CM_ "AUTOGENERATED FILE, DO NOT EDIT";

CM_ "Imported file _community.dbc starts here";
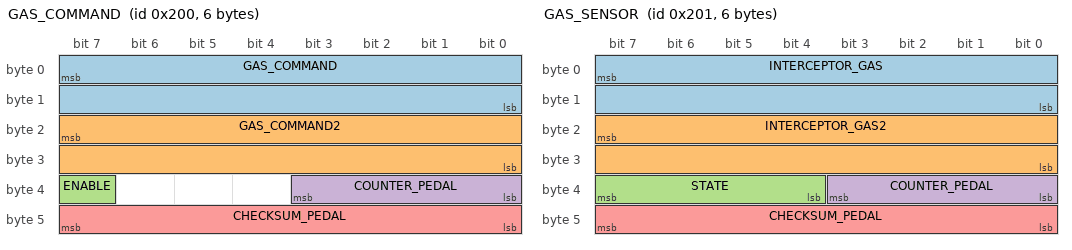
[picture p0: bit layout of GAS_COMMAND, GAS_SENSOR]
BO_ 512 GAS_COMMAND: 6 EON
 SG_ GAS_COMMAND : 7|16@0+ (0.253984064,-83.3) [0|1] "" INTERCEPTOR
 SG_ GAS_COMMAND2 : 23|16@0+ (0.126992032,-83.3) [0|1] "" INTERCEPTOR
 SG_ ENABLE : 39|1@0+ (1,0) [0|1] "" INTERCEPTOR
 SG_ COUNTER_PEDAL : 35|4@0+ (1,0) [0|15] "" INTERCEPTOR
 SG_ CHECKSUM_PEDAL : 47|8@0+ (1,0) [0|255] "" INTERCEPTOR

BO_ 513 GAS_SENSOR: 6 INTERCEPTOR
 SG_ INTERCEPTOR_GAS : 7|16@0+ (1,0) [0|1] "" EON
 SG_ INTERCEPTOR_GAS2 : 23|16@0+ (1,0) [0|1] "" EON
 SG_ STATE : 39|4@0+ (1,0) [0|15] "" EON
 SG_ COUNTER_PEDAL : 35|4@0+ (1,0) [0|15] "" EON
 SG_ CHECKSUM_PEDAL : 47|8@0+ (1,0) [0|255] "" EON

VAL_ 513 STATE 5 "FAULT_TIMEOUT" 4 "FAULT_STARTUP" 3 "FAULT_SCE" 2 "FAULT_SEND" 1 "FAULT_BAD_CHECKSUM" 0 "NO_FAULT" ;

CM_ "Imported file _honda_common.dbc starts here";
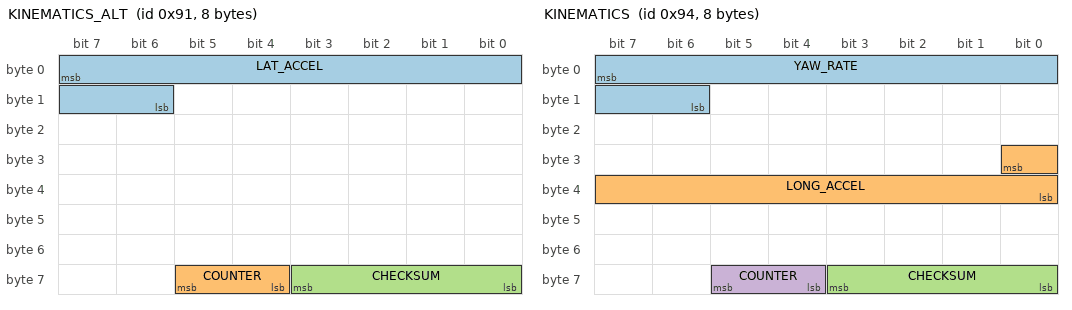
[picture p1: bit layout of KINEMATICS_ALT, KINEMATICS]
BO_ 145 KINEMATICS_ALT: 8 XXX
 SG_ LAT_ACCEL : 7|10@0+ (0.02,-512) [-20|20] "m/s2" EON
 SG_ COUNTER : 61|2@0+ (1,0) [0|3] "" EON
 SG_ CHECKSUM : 59|4@0+ (1,0) [0|3] "" EON

BO_ 148 KINEMATICS: 8 XXX
 SG_ YAW_RATE : 7|10@0+ (0.25,-128) [-128|127.75] "deg/s" EON
 SG_ LONG_ACCEL : 24|9@0- (-0.049,0) [-12.544|12.544] "m/s2" EON
 SG_ CHECKSUM : 59|4@0+ (1,0) [0|3] "" EON
 SG_ COUNTER : 61|2@0+ (1,0) [0|3] "" EON

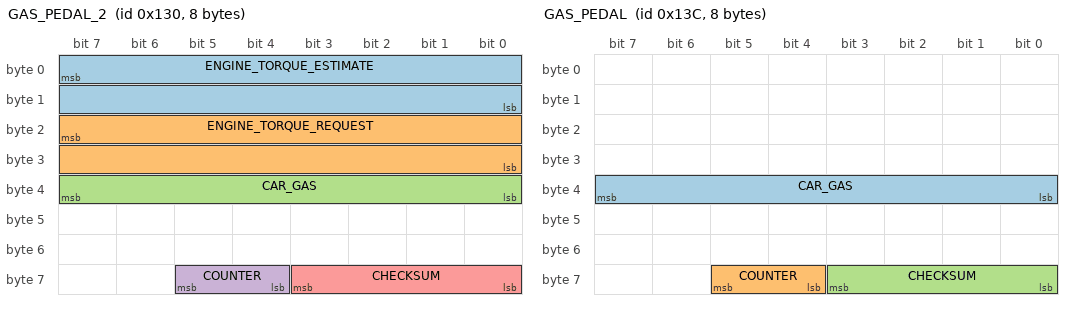
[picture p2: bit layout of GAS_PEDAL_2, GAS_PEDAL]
BO_ 304 GAS_PEDAL_2: 8 PCM
 SG_ ENGINE_TORQUE_ESTIMATE : 7|16@0- (1,0) [-1000|1000] "Nm" EON
 SG_ ENGINE_TORQUE_REQUEST : 23|16@0- (1,0) [-1000|1000] "Nm" EON
 SG_ CAR_GAS : 39|8@0+ (1,0) [0|255] "" EON
 SG_ COUNTER : 61|2@0+ (1,0) [0|3] "" EON
 SG_ CHECKSUM : 59|4@0+ (1,0) [0|15] "" EON

BO_ 316 GAS_PEDAL: 8 PCM
 SG_ CAR_GAS : 39|8@0+ (1,0) [0|255] "" EON
 SG_ COUNTER : 61|2@0+ (1,0) [0|3] "" EON
 SG_ CHECKSUM : 59|4@0+ (1,0) [0|15] "" EON

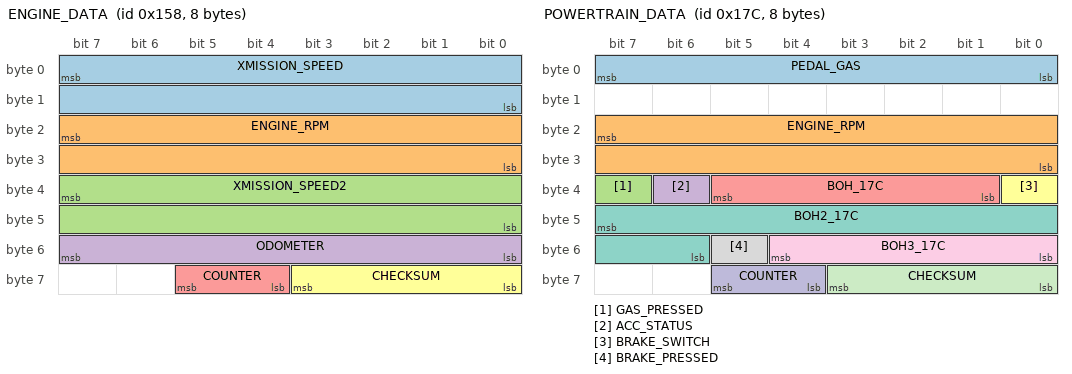
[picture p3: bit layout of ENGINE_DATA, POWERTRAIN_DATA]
BO_ 344 ENGINE_DATA: 8 PCM
 SG_ XMISSION_SPEED : 7|16@0+ (0.01,0) [0|250] "kph" EON
 SG_ ENGINE_RPM : 23|16@0+ (1,0) [0|15000] "rpm" EON
 SG_ XMISSION_SPEED2 : 39|16@0+ (0.01,0) [0|250] "kph" EON
 SG_ ODOMETER : 55|8@0+ (10,0) [0|2550] "m" XXX
 SG_ COUNTER : 61|2@0+ (1,0) [0|3] "" EON
 SG_ CHECKSUM : 59|4@0+ (1,0) [0|15] "" EON

BO_ 380 POWERTRAIN_DATA: 8 PCM
 SG_ PEDAL_GAS : 7|8@0+ (1,0) [0|255] "" EON
 SG_ ENGINE_RPM : 23|16@0+ (1,0) [0|15000] "rpm" EON
 SG_ GAS_PRESSED : 39|1@0+ (1,0) [0|1] "" EON
 SG_ ACC_STATUS : 38|1@0+ (1,0) [0|1] "" EON
 SG_ BOH_17C : 37|5@0+ (1,0) [0|1] "" EON
 SG_ BRAKE_SWITCH : 32|1@0+ (1,0) [0|1] "" EON
 SG_ BOH2_17C : 47|10@0+ (1,0) [0|1] "" EON
 SG_ BRAKE_PRESSED : 53|1@0+ (1,0) [0|1] "" EON
 SG_ BOH3_17C : 52|5@0+ (1,0) [0|1] "" EON
 SG_ COUNTER : 61|2@0+ (1,0) [0|3] "" EON
 SG_ CHECKSUM : 59|4@0+ (1,0) [0|15] "" EON

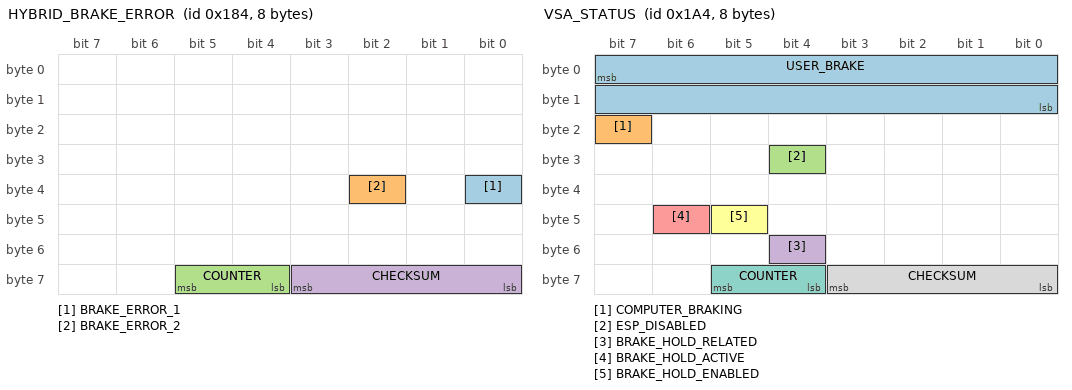
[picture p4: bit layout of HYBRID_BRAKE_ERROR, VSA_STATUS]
BO_ 388 HYBRID_BRAKE_ERROR: 8 XXX
 SG_ BRAKE_ERROR_1 : 32|1@0+ (1,0) [0|1] "" EON
 SG_ BRAKE_ERROR_2 : 34|1@0+ (1,0) [0|1] "" EON
 SG_ COUNTER : 61|2@0+ (1,0) [0|3] "" EON
 SG_ CHECKSUM : 59|4@0+ (1,0) [0|3] "" EON

BO_ 420 VSA_STATUS: 8 VSA
 SG_ USER_BRAKE : 7|16@0+ (0.015625,-1.609375) [0|1000] "" EON
 SG_ COMPUTER_BRAKING : 23|1@0+ (1,0) [0|1] "" EON
 SG_ ESP_DISABLED : 28|1@0+ (1,0) [0|1] "" EON
 SG_ BRAKE_HOLD_RELATED : 52|1@0+ (1,0) [0|1] "" XXX
 SG_ BRAKE_HOLD_ACTIVE : 46|1@0+ (1,0) [0|1] "" EON
 SG_ BRAKE_HOLD_ENABLED : 45|1@0+ (1,0) [0|1] "" EON
 SG_ COUNTER : 61|2@0+ (1,0) [0|3] "" EON
 SG_ CHECKSUM : 59|4@0+ (1,0) [0|15] "" EON

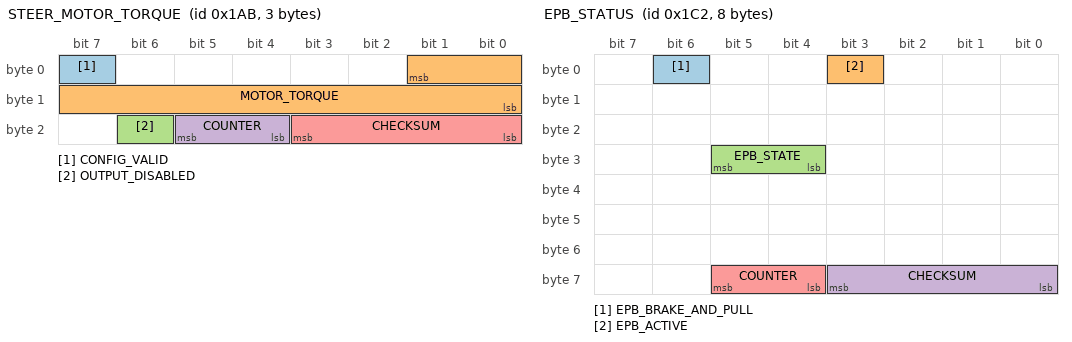
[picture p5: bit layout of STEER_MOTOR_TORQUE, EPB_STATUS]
BO_ 427 STEER_MOTOR_TORQUE: 3 EPS
 SG_ CONFIG_VALID : 7|1@0+ (1,0) [0|1] "" EON
 SG_ MOTOR_TORQUE : 1|10@0+ (1,0) [0|256] "" EON
 SG_ OUTPUT_DISABLED : 22|1@0+ (1,0) [0|1] "" EON
 SG_ COUNTER : 21|2@0+ (1,0) [0|3] "" EON
 SG_ CHECKSUM : 19|4@0+ (1,0) [0|15] "" EON

BO_ 450 EPB_STATUS: 8 XXX
 SG_ EPB_BRAKE_AND_PULL : 6|1@0+ (1,0) [0|1] "" XXX
 SG_ EPB_ACTIVE : 3|1@0+ (1,0) [0|1] "" XXX
 SG_ EPB_STATE : 29|2@0+ (1,0) [0|1] "" XXX
 SG_ CHECKSUM : 59|4@0+ (1,0) [0|15] "" XXX
 SG_ COUNTER : 61|2@0+ (1,0) [0|3] "" XXX

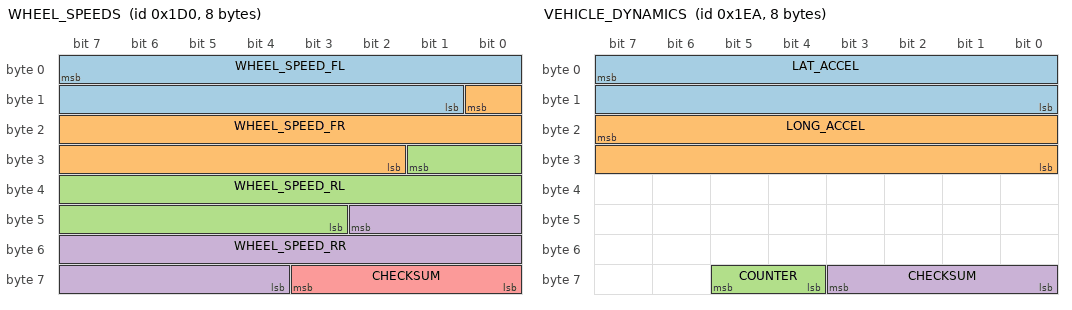
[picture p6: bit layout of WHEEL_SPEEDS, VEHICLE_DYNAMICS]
BO_ 464 WHEEL_SPEEDS: 8 VSA
 SG_ WHEEL_SPEED_FL : 7|15@0+ (0.01,0) [0|250] "kph" EON
 SG_ WHEEL_SPEED_FR : 8|15@0+ (0.01,0) [0|250] "kph" EON
 SG_ WHEEL_SPEED_RL : 25|15@0+ (0.01,0) [0|250] "kph" EON
 SG_ WHEEL_SPEED_RR : 42|15@0+ (0.01,0) [0|250] "kph" EON
 SG_ CHECKSUM : 59|4@0+ (1,0) [0|3] "" EON

BO_ 490 VEHICLE_DYNAMICS: 8 VSA
 SG_ LAT_ACCEL : 7|16@0- (0.0015,0) [-20|20] "m/s2" EON
 SG_ LONG_ACCEL : 23|16@0- (0.0015,0) [-20|20] "m/s2" EON
 SG_ COUNTER : 61|2@0+ (1,0) [0|3] "" EON
 SG_ CHECKSUM : 59|4@0+ (1,0) [0|3] "" EON

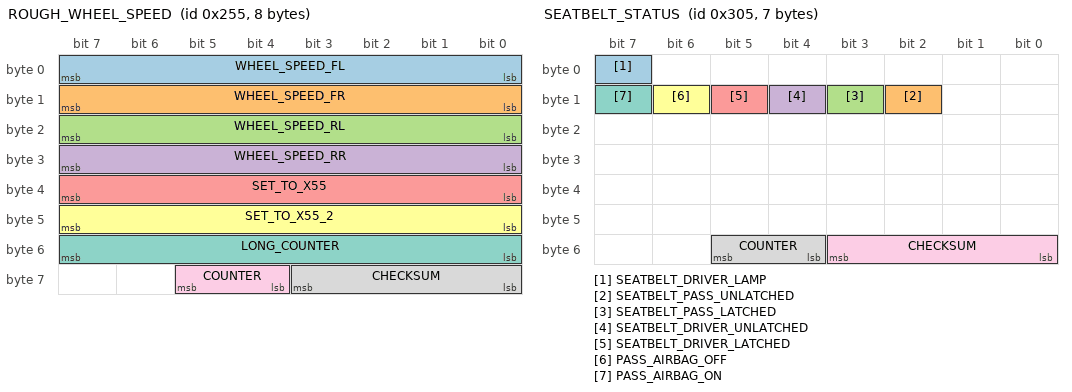
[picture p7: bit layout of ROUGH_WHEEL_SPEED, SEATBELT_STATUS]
BO_ 597 ROUGH_WHEEL_SPEED: 8 VSA
 SG_ WHEEL_SPEED_FL : 7|8@0+ (1,0) [0|255] "kph" EON
 SG_ WHEEL_SPEED_FR : 15|8@0+ (1,0) [0|255] "kph" EON
 SG_ WHEEL_SPEED_RL : 23|8@0+ (1,0) [0|255] "kph" EON
 SG_ WHEEL_SPEED_RR : 31|8@0+ (1,0) [0|255] "kph" EON
 SG_ SET_TO_X55 : 39|8@0+ (1,0) [0|255] "" EON
 SG_ SET_TO_X55_2 : 47|8@0+ (1,0) [0|255] "" EON
 SG_ LONG_COUNTER : 55|8@0+ (1,0) [0|255] "" EON
 SG_ CHECKSUM : 59|4@0+ (1,0) [0|15] "" EON
 SG_ COUNTER : 61|2@0+ (1,0) [0|3] "" EON

BO_ 773 SEATBELT_STATUS: 7 BDY
 SG_ SEATBELT_DRIVER_LAMP : 7|1@0+ (1,0) [0|1] "" EON
 SG_ SEATBELT_PASS_UNLATCHED : 10|1@0+ (1,0) [0|1] "" EON
 SG_ SEATBELT_PASS_LATCHED : 11|1@0+ (1,0) [0|1] "" EON
 SG_ SEATBELT_DRIVER_UNLATCHED : 12|1@0+ (1,0) [0|1] "" EON
 SG_ SEATBELT_DRIVER_LATCHED : 13|1@0+ (1,0) [0|1] "" EON
 SG_ PASS_AIRBAG_OFF : 14|1@0+ (1,0) [0|1] "" EON
 SG_ PASS_AIRBAG_ON : 15|1@0+ (1,0) [0|1] "" EON
 SG_ COUNTER : 53|2@0+ (1,0) [0|3] "" EON
 SG_ CHECKSUM : 51|4@0+ (1,0) [0|3] "" EON

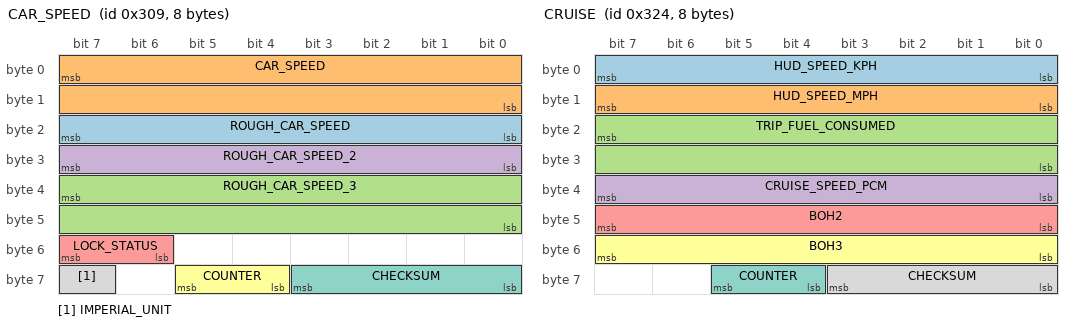
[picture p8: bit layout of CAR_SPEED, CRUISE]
BO_ 777 CAR_SPEED: 8 PCM
 SG_ ROUGH_CAR_SPEED : 23|8@0+ (1,0) [0|255] "mph" XXX
 SG_ CAR_SPEED : 7|16@0+ (0.01,0) [0|65535] "kph" XXX
 SG_ ROUGH_CAR_SPEED_3 : 39|16@0+ (0.01,0) [0|65535] "kph" XXX
 SG_ ROUGH_CAR_SPEED_2 : 31|8@0+ (1,0) [0|255] "mph" XXX
 SG_ LOCK_STATUS : 55|2@0+ (1,0) [0|255] "" XXX
 SG_ COUNTER : 61|2@0+ (1,0) [0|3] "" XXX
 SG_ CHECKSUM : 59|4@0+ (1,0) [0|15] "" XXX
 SG_ IMPERIAL_UNIT : 63|1@0+ (1,0) [0|1] "" XXX

BO_ 780 ACC_HUD: 8 ADAS
 SG_ PCM_SPEED : 7|16@0+ (0.01,0) [0|250] "kph" BDY
 SG_ PCM_GAS : 23|8@0+ (1,0) [0|127] "" BDY
 SG_ CRUISE_SPEED : 31|8@0+ (1,0) [0|255] "kph" BDY
 SG_ DTC_MODE : 39|1@0+ (1,0) [0|1] "" BDY
 SG_ BRAKE_SYSTEM_ICON : 38|1@0+ (1,0) [0|1] "" BDY
 SG_ ACC_PROBLEM : 37|1@0+ (1,0) [0|1] "" BDY
 SG_ FCM_OFF : 35|1@0+ (1,0) [0|1] "" BDY
 SG_ FCM_OFF_2 : 36|1@0+ (1,0) [0|1] "" BDY
 SG_ FCM_PROBLEM : 34|1@0+ (1,0) [0|1] "" BDY
 SG_ RADAR_OBSTRUCTED : 33|1@0+ (1,0) [0|1] "" BDY
 SG_ ENABLE_MINI_CAR : 32|1@0+ (1,0) [0|1] "" BDY
 SG_ HUD_DISTANCE : 47|2@0+ (1,0) [0|3] "" BDY
 SG_ HUD_LEAD : 45|2@0+ (1,0) [0|3] "" BDY
 SG_ BOH_3 : 43|1@0+ (1,0) [0|3] "" BDY
 SG_ BOH_4 : 42|1@0+ (1,0) [0|3] "" BDY
 SG_ BOH_5 : 41|1@0+ (1,0) [0|3] "" BDY
 SG_ CRUISE_CONTROL_LABEL : 40|1@0+ (1,0) [0|3] "" BDY
 SG_ SET_ME_X01_2 : 55|1@0+ (1,0) [0|1] "" BDY
 SG_ IMPERIAL_UNIT : 54|1@0+ (1,0) [0|1] "" BDY
 SG_ ACC_ON : 52|1@0+ (1,0) [0|1] "" BDY
 SG_ CHIME : 51|3@0+ (1,0) [0|1] "" BDY
 SG_ SET_ME_X01 : 48|1@0+ (1,0) [0|1] "" BDY
 SG_ ICONS : 63|2@0+ (1,0) [0|1] "" BDY
 SG_ COUNTER : 61|2@0+ (1,0) [0|3] "" BDY
 SG_ CHECKSUM : 59|4@0+ (1,0) [0|3] "" BDY

BO_ 804 CRUISE: 8 PCM
 SG_ HUD_SPEED_KPH : 7|8@0+ (1,0) [0|255] "kph" EON
 SG_ HUD_SPEED_MPH : 15|8@0+ (1,0) [0|255] "mph" EON
 SG_ TRIP_FUEL_CONSUMED : 23|16@0+ (1,0) [0|255] "" EON
 SG_ CRUISE_SPEED_PCM : 39|8@0+ (1,0) [0|255] "" EON
 SG_ BOH2 : 47|8@0- (1,0) [0|255] "" EON
 SG_ BOH3 : 55|8@0+ (1,0) [0|255] "" EON
 SG_ COUNTER : 61|2@0+ (1,0) [0|3] "" EON
 SG_ CHECKSUM : 59|4@0+ (1,0) [0|15] "" EON

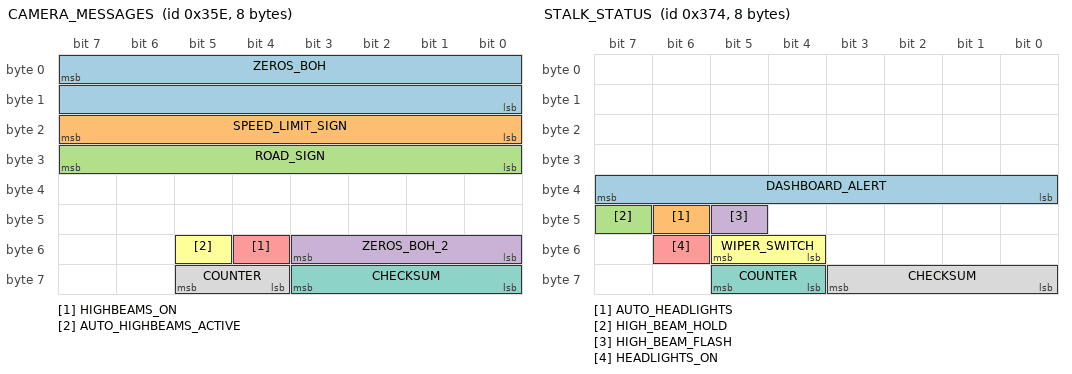
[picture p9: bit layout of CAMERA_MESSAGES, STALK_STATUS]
BO_ 862 CAMERA_MESSAGES: 8 CAM
 SG_ ZEROS_BOH : 7|16@0+ (1,0) [0|127] "" BDY
 SG_ SPEED_LIMIT_SIGN : 23|8@0+ (1,0) [0|255] "" XXX
 SG_ ROAD_SIGN : 31|8@0+ (1,0) [0|255] "" XXX
 SG_ ZEROS_BOH_2 : 51|4@0+ (1,0) [0|15] "" XXX
 SG_ HIGHBEAMS_ON : 52|1@0+ (1,0) [0|1] "" XXX
 SG_ AUTO_HIGHBEAMS_ACTIVE : 53|1@0+ (1,0) [0|1] "" XXX
 SG_ CHECKSUM : 59|4@0+ (1,0) [0|15] "" XXX
 SG_ COUNTER : 61|2@0+ (1,0) [0|3] "" XXX

BO_ 884 STALK_STATUS: 8 XXX
 SG_ DASHBOARD_ALERT : 39|8@0+ (1,0) [0|255] "" EON
 SG_ AUTO_HEADLIGHTS : 46|1@0+ (1,0) [0|1] "" EON
 SG_ HIGH_BEAM_HOLD : 47|1@0+ (1,0) [0|1] "" EON
 SG_ HIGH_BEAM_FLASH : 45|1@0+ (1,0) [0|1] "" EON
 SG_ HEADLIGHTS_ON : 54|1@0+ (1,0) [0|1] "" EON
 SG_ WIPER_SWITCH : 53|2@0+ (1,0) [0|3] "" XXX
 SG_ COUNTER : 61|2@0+ (1,0) [0|3] "" EON
 SG_ CHECKSUM : 59|4@0+ (1,0) [0|15] "" EON

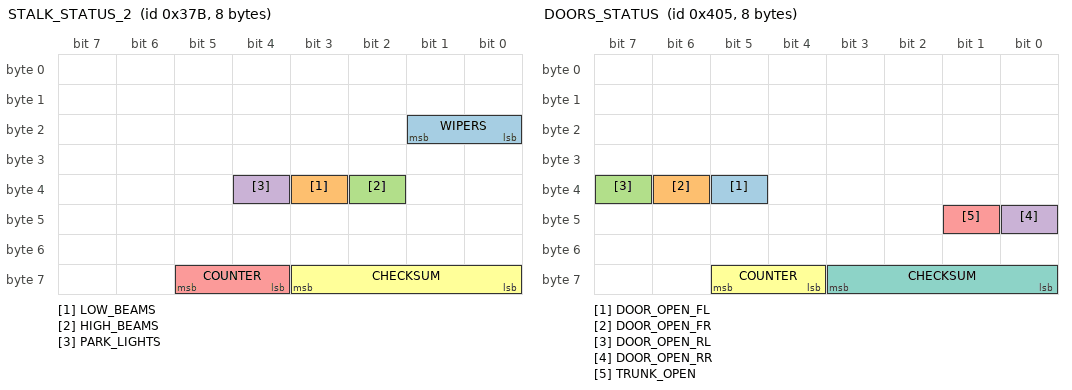
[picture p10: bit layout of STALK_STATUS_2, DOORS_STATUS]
BO_ 891 STALK_STATUS_2: 8 XXX
 SG_ WIPERS : 17|2@0+ (1,0) [0|3] "" EON
 SG_ LOW_BEAMS : 35|1@0+ (1,0) [0|1] "" XXX
 SG_ HIGH_BEAMS : 34|1@0+ (1,0) [0|1] "" XXX
 SG_ PARK_LIGHTS : 36|1@0+ (1,0) [0|1] "" XXX
 SG_ COUNTER : 61|2@0+ (1,0) [0|3] "" EON
 SG_ CHECKSUM : 59|4@0+ (1,0) [0|15] "" EON

BO_ 1029 DOORS_STATUS: 8 BDY
 SG_ DOOR_OPEN_FL : 37|1@0+ (1,0) [0|1] "" EON
 SG_ DOOR_OPEN_FR : 38|1@0+ (1,0) [0|1] "" EON
 SG_ DOOR_OPEN_RL : 39|1@0+ (1,0) [0|1] "" EON
 SG_ DOOR_OPEN_RR : 40|1@0+ (1,0) [0|1] "" EON
 SG_ TRUNK_OPEN : 41|1@0+ (1,0) [0|1] "" EON
 SG_ COUNTER : 61|2@0+ (1,0) [0|3] "" EON
 SG_ CHECKSUM : 59|4@0+ (1,0) [0|15] "" EON

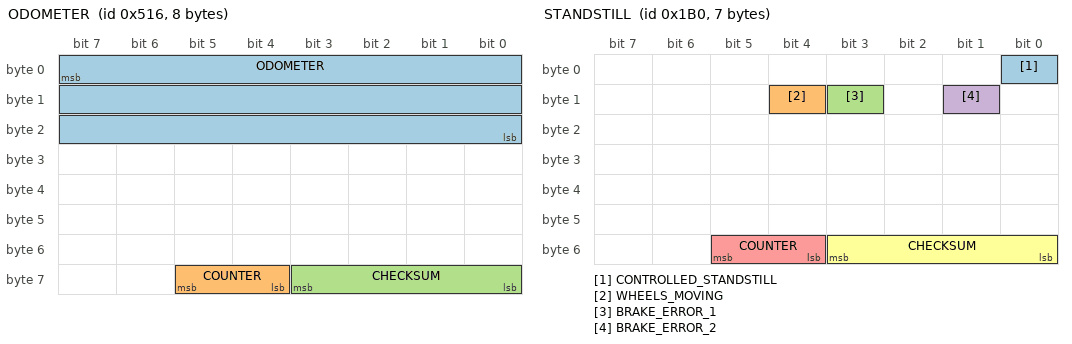
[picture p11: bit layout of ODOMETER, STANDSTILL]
BO_ 1302 ODOMETER: 8 XXX
 SG_ ODOMETER : 7|24@0+ (1,0) [0|16777215] "km" EON
 SG_ COUNTER : 61|2@0+ (1,0) [0|3] "" EON
 SG_ CHECKSUM : 59|4@0+ (1,0) [0|3] "" EON

CM_ SG_ 304 "Seems to be platform-agnostic";
CM_ SG_ 316 "Should exist on Nidec";
CM_ SG_ 420 BRAKE_HOLD_RELATED "On when Brake Hold engaged";
CM_ SG_ 490 LONG_ACCEL "wheel speed derivative, noisy and zero snapping";
CM_ SG_ 773 PASS_AIRBAG_ON "Might just be indicator light";
CM_ SG_ 773 PASS_AIRBAG_OFF "Might just be indicator light";
CM_ SG_ 780 CRUISE_SPEED "255 = no speed";
CM_ SG_ 780 PCM_SPEED "Used by Nidec";
CM_ SG_ 780 PCM_GAS "Used by Nidec";
CM_ SG_ 804 CRUISE_SPEED_PCM "255 = no speed";
CM_ SG_ 148 YAW_RATE "Vehicle yaw rate from the chassis yaw sensor, positive = clockwise (right turn), nominal zero 512 counts. Each car sits a few counts off that zero (2018 Clarity 508, 2019 Civic Bosch 513, both constant at every standstill), so learn it at standstill. Scale checked against GPS heading: Clarity 0.2494-0.2522, Civic Bosch 0.241-0.245 deg/s per count. Replaces an unused LAT_ACCEL definition (0.02, -512) that was not lateral acceleration.";
CM_ SG_ 148 LONG_ACCEL "Longitudinal accelerometer, gravity included (reads road grade at standstill), positive = accelerating. -0.049 m/s2 per count (about 0.005 g) against the comma IMU on 17 Clarity and 2 Civic Bosch routes, correlation 0.98-0.998; the former -0.02 read 2.4x low.";

CM_ SG_ 148 YAW_RATE "Vehicle yaw rate from the chassis yaw sensor, positive = clockwise (right turn), nominal zero 512 counts. Each car sits a few counts off that zero (2018 Clarity 508, 2019 Civic Bosch 513, both constant at every standstill), so learn it at standstill. Scale checked against GPS heading: Clarity 0.2494-0.2522, Civic Bosch 0.241-0.245 deg/s per count. Replaces an unused LAT_ACCEL definition (0.02, -512) that was not lateral acceleration.";
CM_ SG_ 148 LONG_ACCEL "Longitudinal accelerometer, gravity included (reads road grade at standstill), positive = accelerating. -0.049 m/s2 per count (about 0.005 g) against the comma IMU on 17 Clarity and 2 Civic Bosch routes, correlation 0.98-0.998; the former -0.02 read 2.4x low.";

VAL_ 450 EPB_STATE 3 "engaged" 2 "disengaging" 1 "engaging" 0 "disengaged" ;
VAL_ 780 CRUISE_SPEED 255 "no_speed" 252 "stopped";
VAL_ 780 HUD_LEAD 3 "acc_off" 2 "solid_car" 1 "dashed_car" 0 "no_car";
VAL_ 884 DASHBOARD_ALERT 0 "none" 51 "acc_problem" 55 "cmbs_problem" 75 "key_not_detected" 79 "fasten_seatbelt" 111 "lkas_problem" 131 "brake_system_problem" 132 "brake_hold_problem" 139 "tbd" 161 "door_open";
VAL_ 891 WIPERS 4 "High" 2 "Low" 0 "Off";

CM_ "Imported file _nidec_common.dbc starts here";
BO_ 432 STANDSTILL: 7 VSA
 SG_ CONTROLLED_STANDSTILL : 0|1@0+ (1,0) [0|1] "" EON
 SG_ WHEELS_MOVING : 12|1@0+ (1,0) [0|1] "" EON
 SG_ BRAKE_ERROR_1 : 11|1@0+ (1,0) [0|1] "" EON
 SG_ BRAKE_ERROR_2 : 9|1@0+ (1,0) [0|1] "" EON
 SG_ COUNTER : 53|2@0+ (1,0) [0|3] "" EON
 SG_ CHECKSUM : 51|4@0+ (1,0) [0|3] "" EON

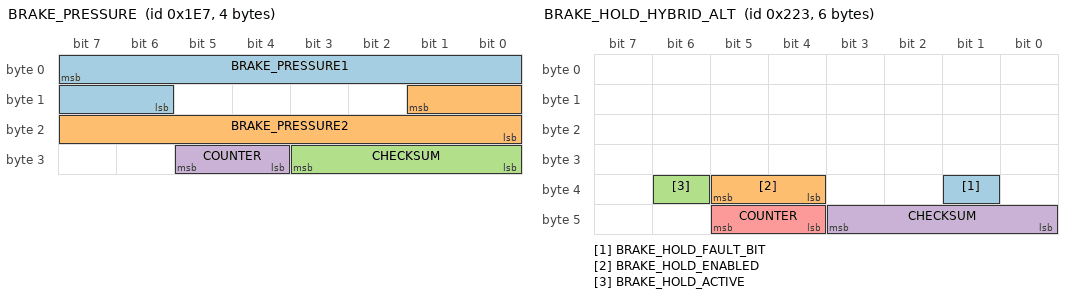
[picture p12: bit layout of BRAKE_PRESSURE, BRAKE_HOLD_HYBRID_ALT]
BO_ 487 BRAKE_PRESSURE: 4 VSA
 SG_ BRAKE_PRESSURE1 : 7|10@0+ (0.015625,-103) [0|1000] "" EON
 SG_ BRAKE_PRESSURE2 : 9|10@0+ (0.015625,-103) [0|1000] "" EON
 SG_ CHECKSUM : 27|4@0+ (1,0) [0|15] "" EON
 SG_ COUNTER : 29|2@0+ (1,0) [0|3] "" EON

BO_ 506 BRAKE_COMMAND: 8 ADAS
 SG_ COMPUTER_BRAKE : 7|10@0+ (1,0) [0|1] "" EBCM
 SG_ BRAKE_PUMP_REQUEST : 8|1@0+ (1,0) [0|1] "" EBCM
 SG_ BRAKE_PUMP_REQUEST_HYBRID : 11|1@0+ (1,0) [0|1] "" EBCM
 SG_ SET_ME_X00 : 23|3@0+ (1,0) [0|1] "" EBCM
 SG_ CRUISE_OVERRIDE : 20|1@0+ (1,0) [0|1] "" EBCM
 SG_ SET_ME_X00_2 : 19|1@0+ (1,0) [0|1] "" EBCM
 SG_ CRUISE_FAULT_CMD : 18|1@0+ (1,0) [0|1] "" EBCM
 SG_ CRUISE_CANCEL_CMD : 17|1@0+ (1,0) [0|1] "" EBCM
 SG_ COMPUTER_BRAKE_REQUEST : 16|1@0+ (1,0) [0|1] "" EBCM
 SG_ SET_ME_1 : 31|1@0+ (1,0) [0|1] "" EBCM
 SG_ AEB_REQ_1 : 29|1@0+ (1,0) [0|1] "" XXX
 SG_ AEB_REQ_2 : 26|3@0+ (1,0) [0|7] "" XXX
 SG_ BRAKE_LIGHTS : 39|1@0+ (1,0) [0|1] "" EBCM
 SG_ CRUISE_STATES : 38|7@0+ (1,0) [0|1] "" EBCM
 SG_ CHIME : 47|3@0+ (1,0) [0|7] "" EBCM
 SG_ SET_ME_X00_3 : 44|1@0+ (1,0) [0|1] "" EBCM
 SG_ FCW : 43|2@0+ (1,0) [0|3] "" EBCM
 SG_ AEB_STATUS : 41|2@0+ (1,0) [0|3] "" XXX
 SG_ COMPUTER_BRAKE_HYBRID : 55|10@0+ (1,0) [0|0] "" EBCM
 SG_ COUNTER : 61|2@0+ (1,0) [0|3] "" EBCM
 SG_ CHECKSUM : 59|4@0+ (1,0) [0|15] "" EBCM

BO_ 547 BRAKE_HOLD_HYBRID_ALT: 6 XXX
 SG_ BRAKE_HOLD_FAULT_BIT : 33|1@0+ (1,0) [0|1] "" XXX
 SG_ BRAKE_HOLD_ENABLED : 37|2@0+ (1,0) [0|7] "" XXX
 SG_ BRAKE_HOLD_ACTIVE : 38|1@0+ (1,0) [0|1] "" XXX
 SG_ CHECKSUM : 43|4@0+ (1,0) [0|15] "" XXX
 SG_ COUNTER : 45|2@0+ (1,0) [0|3] "" XXX

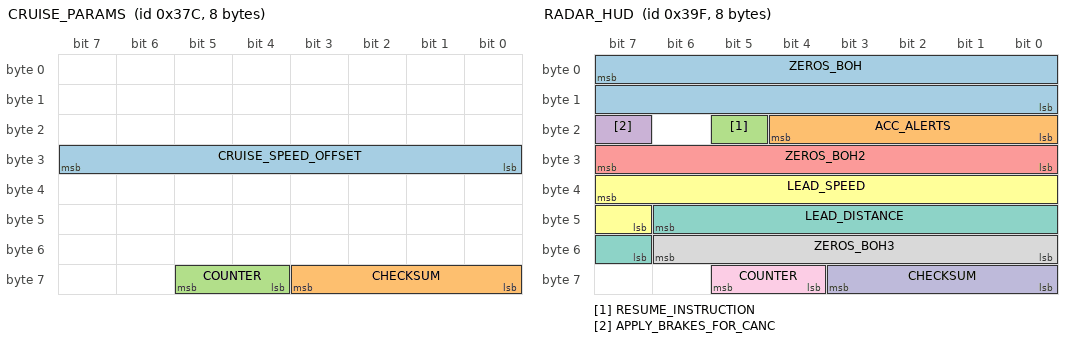
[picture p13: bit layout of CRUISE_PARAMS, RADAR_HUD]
BO_ 892 CRUISE_PARAMS: 8 PCM
 SG_ CRUISE_SPEED_OFFSET : 31|8@0- (0.1,0) [-128|127] "kph" EON
 SG_ CHECKSUM : 59|4@0+ (1,0) [0|3] "" EON
 SG_ COUNTER : 61|2@0+ (1,0) [0|3] "" EON

BO_ 927 RADAR_HUD: 8 ADAS
 SG_ ZEROS_BOH : 7|16@0+ (1,0) [0|127] "" BDY
 SG_ ACC_ALERTS : 20|5@0+ (1,0) [0|15] "" BDY
 SG_ RESUME_INSTRUCTION : 21|1@0+ (1,0) [0|15] "" BDY
 SG_ APPLY_BRAKES_FOR_CANC : 23|1@0+ (1,0) [0|15] "" BDY
 SG_ ZEROS_BOH2 : 31|8@0+ (1,0) [0|127] "" BDY
 SG_ LEAD_SPEED : 39|9@0+ (1,0) [0|127] "" BDY
 SG_ LEAD_DISTANCE : 46|8@0+ (1,0) [0|31] "" BDY
 SG_ ZEROS_BOH3 : 54|7@0+ (1,0) [0|127] "" BDY
 SG_ COUNTER : 61|2@0+ (1,0) [0|3] "" BDY
 SG_ CHECKSUM : 59|4@0+ (1,0) [0|15] "" BDY

CM_ SG_ 506 AEB_REQ_1 "set for duration of suspected AEB event";
CM_ SG_ 506 COMPUTER_BRAKE_HYBRID "Used by Hybrid Nidec";
CM_ SG_ 506 BRAKE_PUMP_REQUEST_HYBRID "Used by Hybrid Nidec";

VAL_ 506 FCW 3 "fcw" 2 "fcw" 1 "fcw" 0 "no_fcw";
VAL_ 506 CHIME 4 "double_chime" 3 "single_chime" 2 "continuous_chime" 1 "repeating_chime" 0 "no_chime";
VAL_ 506 AEB_STATUS 3 "aeb_prepare" 2 "aeb_ready" 1 "aeb_braking" 0 "no_aeb";
VAL_ 927 ACC_ALERTS 29 "esp_active_acc_canceled" 10 "b_pedal_applied" 9 "speed_too_low" 8 "speed_too_high" 7 "p_brake_applied" 6 "gear_no_d" 5 "seatbelt" 4 "too_steep_downhill" 3 "too_steep_uphill" 2 "too_close" 1 "no_vehicle_ahead" ;
VAL_ 927 LEAD_DISTANCE 254 "no lead";
VAL_ 927 LEAD_SPEED 510 "no lead";

CM_ "Imported file _lkas_hud_5byte.dbc starts here";
BO_ 829 LKAS_HUD: 5 ADAS
 SG_ LKAS_READY : 0|1@0+ (1,0) [0|127] "" BDY
 SG_ LKAS_STATE_CHANGE : 6|1@0+ (1,0) [0|1] "" XXX
 SG_ CAM_TEMP_HIGH : 7|1@0+ (1,0) [0|255] "" BDY
 SG_ DASHED_LANES : 14|1@0+ (1,0) [0|1] "" BDY
 SG_ DTC : 13|1@0+ (1,0) [0|1] "" BDY
 SG_ LKAS_PROBLEM : 12|1@0+ (1,0) [0|1] "" BDY
 SG_ LKAS_OFF : 11|1@0+ (1,0) [0|1] "" BDY
 SG_ SOLID_LANES : 10|1@0+ (1,0) [0|1] "" BDY
 SG_ CLEAN_WINDSHIELD : 26|1@0+ (1,0) [0|1] "" BDY
 SG_ STEERING_REQUIRED : 8|1@0+ (1,0) [0|1] "" BDY
 SG_ BEEP : 17|2@0+ (1,0) [0|1] "" BDY
 SG_ RDM_PROBLEM : 21|1@0+ (1,0) [0|1] "" BDY
 SG_ RDM_HUD : 9|1@0+ (1,0) [0|1] "" BDY
 SG_ RDM_HUD_2 : 23|1@0+ (1,0) [0|1] "" XXX
 SG_ RDM_OFF : 27|1@0+ (1,0) [0|1] "" BDY
 SG_ RDM_ON : 20|1@0+ (1,0) [0|1] "" XXX
 SG_ RDM_ON_2 : 28|1@0+ (1,0) [0|1] "" BDY
 SG_ LANE_ASSIST_BEEP_OFF : 30|1@0+ (1,0) [0|1] "" XXX
 SG_ CHECKSUM : 35|4@0+ (1,0) [0|15] "" BDY
 SG_ COUNTER : 37|2@0+ (1,0) [0|3] "" BDY

CM_ SG_ 829 BEEP "beeps are pleasant, chimes are for warnings etc...";
CM_ SG_ 829 CAM_TEMP_HIGH "Some Driver Assist Systems Cannot Operate: Camera Temperature Too High";
CM_ SG_ 829 CAMERA_OVERHEAT "Lane Keeping Assist Cannot Operate: Camera Too Hot";

VAL_ 829 BEEP 5 "solid_beep" 4 "double_beep" 3 "single_beep" 2 "triple_beep" 1 "repeated_beep" 0 "no_beep";

CM_ "Imported file _nidec_scm_group_b.dbc starts here";
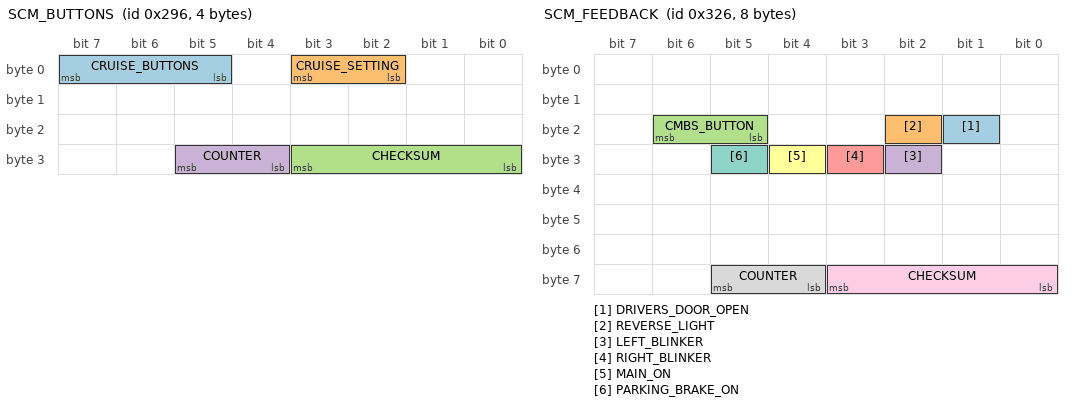
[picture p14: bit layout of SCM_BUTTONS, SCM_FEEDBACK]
BO_ 662 SCM_BUTTONS: 4 SCM
 SG_ CRUISE_BUTTONS : 7|3@0+ (1,0) [0|7] "" EON
 SG_ CRUISE_SETTING : 3|2@0+ (1,0) [0|3] "" EON
 SG_ CHECKSUM : 27|4@0+ (1,0) [0|3] "" EON
 SG_ COUNTER : 29|2@0+ (1,0) [0|3] "" EON

BO_ 806 SCM_FEEDBACK: 8 SCM
 SG_ DRIVERS_DOOR_OPEN : 17|1@0+ (1,0) [0|1] "" XXX
 SG_ REVERSE_LIGHT : 18|1@0+ (1,0) [0|1] "" EON
 SG_ CMBS_BUTTON : 22|2@0+ (1,0) [0|3] "" EON
 SG_ LEFT_BLINKER : 26|1@0+ (1,0) [0|1] "" EON
 SG_ RIGHT_BLINKER : 27|1@0+ (1,0) [0|1] "" EON
 SG_ MAIN_ON : 28|1@0+ (1,0) [0|1] "" EON
 SG_ PARKING_BRAKE_ON : 29|1@0+ (1,0) [0|1] "" XXX
 SG_ COUNTER : 61|2@0+ (1,0) [0|3] "" EON
 SG_ CHECKSUM : 59|4@0+ (1,0) [0|15] "" EON

VAL_ 662 CRUISE_BUTTONS 7 "tbd" 6 "tbd" 5 "tbd" 4 "accel_res" 3 "decel_set" 2 "cancel" 1 "main" 0 "none" ;
VAL_ 662 CRUISE_SETTING 3 "distance_adj" 2 "tbd" 1 "lkas_button" 0 "none" ;
VAL_ 806 CMBS_BUTTON 3 "pressed" 0 "released" ;

CM_ "Imported file _steering_sensors_a.dbc starts here";
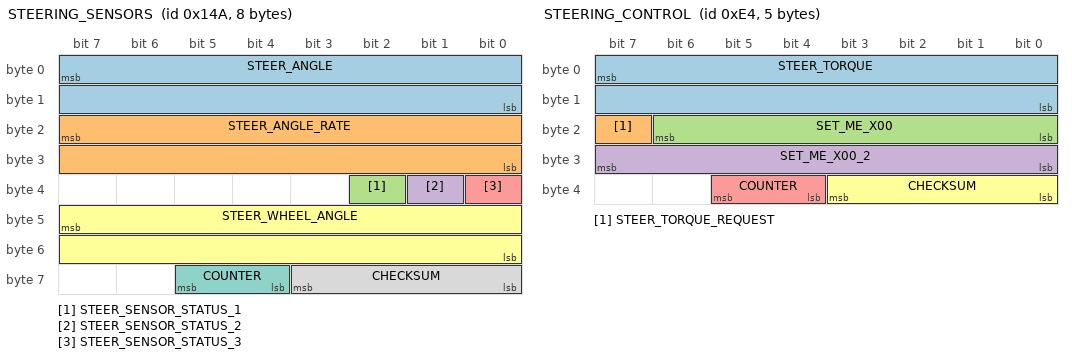
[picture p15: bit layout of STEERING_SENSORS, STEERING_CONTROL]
BO_ 330 STEERING_SENSORS: 8 EPS
 SG_ STEER_ANGLE : 7|16@0- (-0.1,0) [-500|500] "deg" EON
 SG_ STEER_ANGLE_RATE : 23|16@0- (-1,0) [-3000|3000] "deg/s" EON
 SG_ STEER_SENSOR_STATUS_1 : 34|1@0+ (1,0) [0|1] "" EON
 SG_ STEER_SENSOR_STATUS_2 : 33|1@0+ (1,0) [0|1] "" EON
 SG_ STEER_SENSOR_STATUS_3 : 32|1@0+ (1,0) [0|1] "" EON
 SG_ STEER_WHEEL_ANGLE : 47|16@0- (-0.1,0) [-500|500] "deg" EON
 SG_ COUNTER : 61|2@0+ (1,0) [0|3] "" EON
 SG_ CHECKSUM : 59|4@0+ (1,0) [0|15] "" EON

CM_ "Imported file _steering_control_a.dbc starts here";
BO_ 228 STEERING_CONTROL: 5 ADAS
 SG_ STEER_TORQUE : 7|16@0- (1,0) [-3840|3840] "" EPS
 SG_ STEER_TORQUE_REQUEST : 23|1@0+ (1,0) [0|1] "" EPS
 SG_ SET_ME_X00 : 22|7@0+ (1,0) [0|127] "" EPS
 SG_ SET_ME_X00_2 : 31|8@0+ (1,0) [0|0] "" EPS
 SG_ COUNTER : 37|2@0+ (1,0) [0|3] "" EPS
 SG_ CHECKSUM : 35|4@0+ (1,0) [0|15] "" EPS

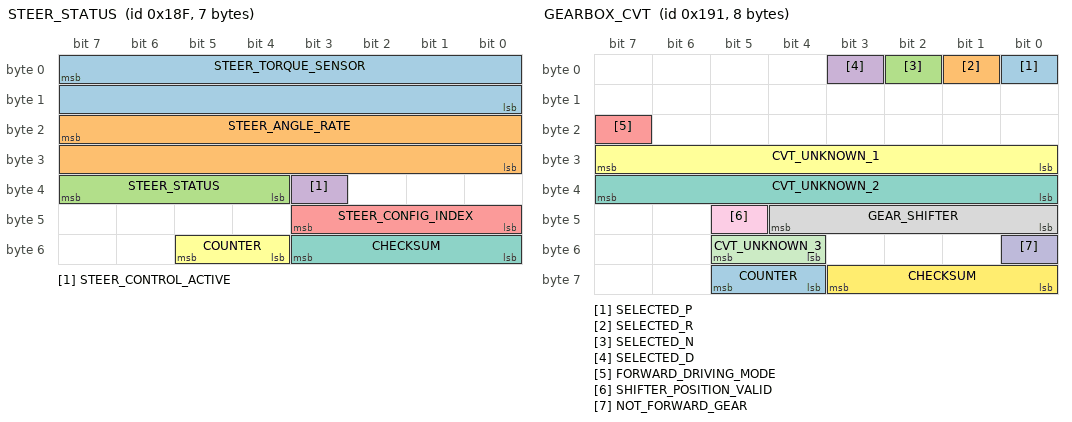
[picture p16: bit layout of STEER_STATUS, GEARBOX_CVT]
BO_ 399 STEER_STATUS: 7 EPS
 SG_ STEER_TORQUE_SENSOR : 7|16@0- (-1,0) [-31000|31000] "tbd" EON
 SG_ STEER_ANGLE_RATE : 23|16@0- (-0.1,0) [-31000|31000] "deg/s" EON
 SG_ STEER_STATUS : 39|4@0+ (1,0) [0|15] "" EON
 SG_ STEER_CONTROL_ACTIVE : 35|1@0+ (1,0) [0|1] "" EON
 SG_ STEER_CONFIG_INDEX : 43|4@0+ (1,0) [0|15] "" EON
 SG_ COUNTER : 53|2@0+ (1,0) [0|3] "" EON
 SG_ CHECKSUM : 51|4@0+ (1,0) [0|3] "" EON

VAL_ 399 STEER_STATUS 7 "permanent_fault" 6 "tmp_fault" 5 "fault_1" 4 "no_torque_alert_2" 3 "low_speed_lockout" 2 "no_torque_alert_1" 1 "driver_steering" 0 "normal" ;

CM_ "Imported file _gearbox_common.dbc starts here";
BO_ 401 GEARBOX_CVT: 8 PCM
 SG_ SELECTED_P : 0|1@0+ (1,0) [0|1] "" XXX
 SG_ SELECTED_R : 1|1@0+ (1,0) [0|1] "" XXX
 SG_ SELECTED_N : 2|1@0+ (1,0) [0|1] "" XXX
 SG_ SELECTED_D : 3|1@0+ (1,0) [0|1] "" XXX
 SG_ FORWARD_DRIVING_MODE : 23|1@0+ (1,0) [0|1] "" XXX
 SG_ CVT_UNKNOWN_1 : 31|8@0+ (1,0) [0|255] "" XXX
 SG_ CVT_UNKNOWN_2 : 39|8@0+ (1,0) [0|255] "" XXX
 SG_ GEAR_SHIFTER : 44|5@0+ (1,0) [0|31] "" XXX
 SG_ SHIFTER_POSITION_VALID : 45|1@0+ (1,0) [0|1] "" XXX
 SG_ NOT_FORWARD_GEAR : 48|1@0+ (1,0) [0|1] "" XXX
 SG_ CVT_UNKNOWN_3 : 53|2@0+ (1,0) [0|3] "" XXX
 SG_ CHECKSUM : 59|4@0+ (1,0) [0|15] "" EON
 SG_ COUNTER : 61|2@0+ (1,0) [0|3] "" EON

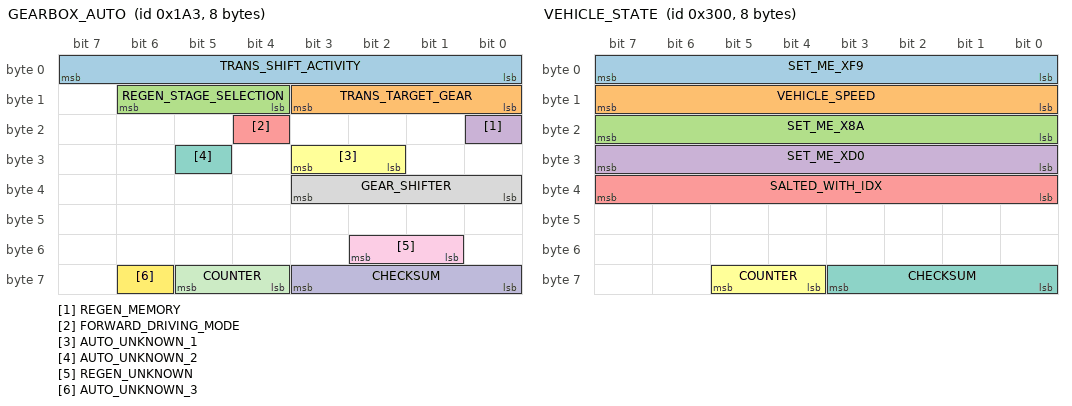
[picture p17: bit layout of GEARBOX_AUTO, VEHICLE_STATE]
BO_ 419 GEARBOX_AUTO: 8 PCM
 SG_ TRANS_SHIFT_ACTIVITY : 7|8@0+ (1,0) [0|256] "" EON
 SG_ TRANS_TARGET_GEAR : 11|4@0+ (1,0) [0|15] "" XXX
 SG_ REGEN_STAGE_SELECTION : 14|3@0+ (1,0) [0|7] "Stage" XXX
 SG_ REGEN_MEMORY : 16|1@0+ (1,0) [0|1] "" XXX
 SG_ FORWARD_DRIVING_MODE : 20|1@0+ (1,0) [0|1] "" XXX
 SG_ AUTO_UNKNOWN_1 : 27|2@0+ (1,0) [0|3] "" XXX
 SG_ AUTO_UNKNOWN_2 : 29|1@0+ (1,0) [0|1] "" XXX
 SG_ GEAR_SHIFTER : 35|4@0+ (1,0) [0|15] "" EON
 SG_ REGEN_UNKNOWN : 50|2@0+ (1,0) [0|3] "" XXX
 SG_ CHECKSUM : 59|4@0+ (1,0) [0|3] "" EON
 SG_ COUNTER : 61|2@0+ (1,0) [0|3] "" EON
 SG_ AUTO_UNKNOWN_3 : 62|1@0+ (1,0) [0|1] "" XXX

CM_ SG_ 401 CVT_UNKNOWN_1 "Probably measured/actual CVT ratio";
CM_ SG_ 401 CVT_UNKNOWN_2 "Probably target/commanded CVT ratio";
CM_ SG_ 419 TRANS_SHIFT_ACTIVITY "Tracks but trails TRANS_TARGET_GEAR with extra activity, probable solenoid activations or TC lockup";
CM_ SG_ 419 REGEN_STAGE_SELECTION "Driver-selected regenerative braking threshold";
CM_ SG_ 419 REGEN_MEMORY "Driver-selected persistence setting, M shown in instrument cluster";
CM_ SG_ 419 REGEN_UNKNOWN "Both bits set when user enables regen, otherwise zero";

VAL_ 401 GEAR_SHIFTER 1 "P" 2 "R" 3 "N" 4 "D" 7 "L" 10 "S" 11 "B";
VAL_ 419 GEAR_SHIFTER 1 "P" 2 "R" 3 "N" 4 "D" 7 "L" 10 "S" 11 "B";
VAL_ 419 TRANS_TARGET_GEAR 0 "None / Neutral / Park" 1 "1st" 2 "2nd" 3 "3rd" 4 "4th" 5 "5th" 6 "6th" 7 "7th" 8 "8th" 9 "9th" 10 "10th" 13 "Reverse";
VAL_ 419 REGEN_STAGE_SELECTION 0 "disabled" 1 "stage_1" 2 "stage_2" 3 "stage_3" 4 "stage_4" 5 "stage_5" 6 "stage_6";
VAL_ 419 REGEN_MEMORY 0 "disabled" 1 "persistent";

CM_ "honda_clarity_hybrid_2018_can.dbc starts here";

BO_ 768 VEHICLE_STATE: 8 ADAS
 SG_ SET_ME_XF9 : 7|8@0+ (1,0) [0|255] "" Vector__XXX
 SG_ VEHICLE_SPEED : 15|8@0+ (1,0) [0|255] "kph" Vector__XXX
 SG_ SET_ME_X8A : 23|8@0+ (1,0) [0|255] "" XXX
 SG_ SET_ME_XD0 : 31|8@0+ (1,0) [0|255] "" XXX
 SG_ SALTED_WITH_IDX : 39|8@0+ (1,0) [0|255] "" XXX
 SG_ COUNTER : 61|2@0+ (1,0) [0|3] "" XXX
 SG_ CHECKSUM : 59|4@0+ (1,0) [0|15] "" XXX

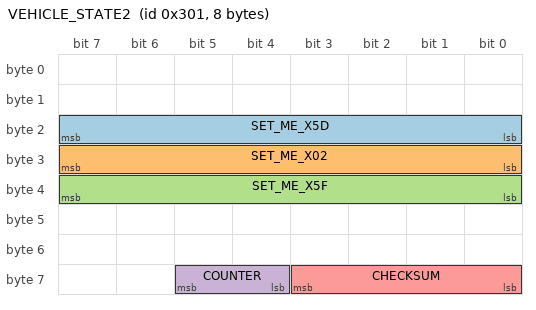
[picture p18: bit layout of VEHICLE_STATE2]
BO_ 769 VEHICLE_STATE2: 8 ADAS
 SG_ SET_ME_X5D : 23|8@0+ (1,0) [0|255] "" XXX
 SG_ SET_ME_X02 : 31|8@0+ (1,0) [0|255] "" XXX
 SG_ SET_ME_X5F : 39|8@0+ (1,0) [0|255] "" XXX
 SG_ COUNTER : 61|2@0+ (1,0) [0|3] "" XXX
 SG_ CHECKSUM : 59|4@0+ (1,0) [0|15] "" XXX
